# haltium_sysctrl register map
Vendor: Nordic Semiconductor; Series: nRFHaltium; File version: 1
Registers are 32-bit, read-write, reset 0x0 unless marked. A register's access mark holds for its fields unless they carry their own. Offsets are from the block's base; [hi:lo] are bit positions; lines under a group give offsets from that group; {n}, {i} and the like mark numbered series.

## CLIC_S — Core-Local Interrupt Controller
Base 0x5F8C8000
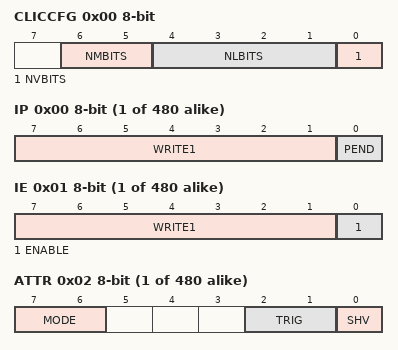
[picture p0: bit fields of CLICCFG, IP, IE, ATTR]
0x00 CLICCFG 8-bit ro — CLIC configuration.
  [6:5] NMBITS — Interrupt previlage mode.
    0=ModeM (All interrupts are M-mode only); 1=ModeS (Interrupts can be S-mode); 2=ModeSU (Interrupts can be S-mode or U-mode)
  [4:1] NLBITS — Interrupt level encoding.
  [0] NVBITS — Selective interrupt hardware vectoring.
    0=NotImplemented (Selective interrupt hardware vectoring is not implemented); 1=Implemented (Selective interrupt hardware vectoring is implemented)
{0x4+i} CLICINFO[{i}] (i=0..3) 8-bit ro — Description collection: CLIC information.
  [7:0] CLICINFO — CLIC information.
{0x1000+4i} CLICINT[{i}] (i=0..479) group — Unspecified
  0x00 IP 8-bit — Description cluster: Interrupt pending for IRQ number [n].
    [7:1] WRITE1 — Read as zero, write 1.
    [0] PEND — Interrupt Pending bit.
      0=NotPending (Interrupt not pending); 1=Pending (Interrupt pending)
  0x01 IE 8-bit — Description cluster: Interrupt enable for IRQ number [n].
    [7:1] WRITE1 — Read as zero, write 1.
    [0] ENABLE — Interrupt enable bit.
      0=Disabled (Interrupt disabled); 1=Enabled (Interrupt enabled)
  0x02 ATTR 8-bit — Description cluster: CLIC Interrupt Attribute Register
    [7:6] MODE — Privilege mode.
      0=UserMode; 1=SupervisorMode; 3=MachineMode
    [2:1] TRIG — Trigger type and polarity for each interrupt input.
      0=EdgeTriggered (Interrupts are edge-triggered); 1=LevelTriggered (Interrupts are level-triggered); 2=NegativeEdge (Interrupts are negative edge-triggered); 3=PositiveEdge (Interrupts are positive edge-triggered)
    [0] SHV — Selective Hardware Vectoring.
      0=NonVectored (Interrupt to be non-vectored); 1=Vectored (Hardware vectored)
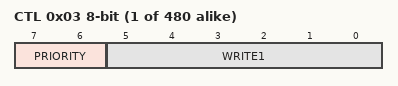
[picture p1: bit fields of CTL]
  0x03 CTL 8-bit — Description cluster: Interrupt priority for IRQ number [n].
    [7:6] PRIORITY — Interrupt priority.
    [5:0] WRITE1 — Read as zero, write 1.

## GLRC0_S — LRC 0
Base 0x5F8CE000
Same registers: GLRC1_S 0x5F93E000
{0x0+4i} TASKS_CLKSTART[{i}] (i=0..7) wo — Description collection: Start the clock source [n]
  [0] TASKS_CLKSTART — Start the clock source [n]
    1=Trigger task
{0x20+4i} TASKS_CLKSTOP[{i}] (i=0..7) wo — Description collection: Clear the TASKS_CLKSTART[n] request
  [0] TASKS_CLKSTOP — Clear the TASKS_CLKSTART[n] request
    1=Trigger task
0x40 TASKS_CONSTLAT wo — Enable constant latency mode
  [0] TASKS_CONSTLAT
    1=Trigger task
0x44 TASKS_LOWPWR wo — Enable Low Power mode
  [0] TASKS_LOWPWR
    1=Trigger task
{0x100+4i} EVENTS_CLKSTARTED[{i}] (i=0..7) — Description collection: Clock [n] started
  [0] EVENTS_CLKSTARTED — Clock [n] started
    0=NotGenerated (Event not generated); 1=Generated (Event generated)
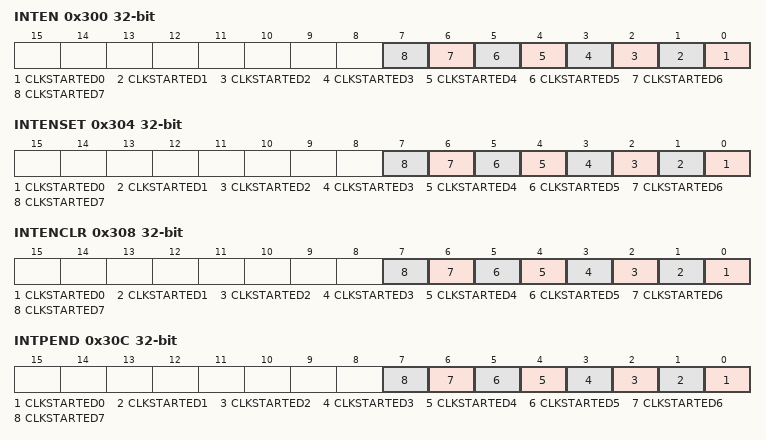
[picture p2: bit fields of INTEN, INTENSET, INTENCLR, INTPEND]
0x300 INTEN — Enable or disable interrupt
  [all] fields
    0=Disabled; 1=Enabled
  [n] CLKSTARTED{n} (n=0..7) — Enable or disable interrupt for event CLKSTARTED[{n}]
0x304 INTENSET — Enable interrupt
  [all] fields
    on read: 0=Disabled (Read: Disabled); 1=Enabled (Read: Enabled) | on write: 1=Set (Enable)
  [n] CLKSTARTED{n} (n=0..7) — Write '1' to enable interrupt for event CLKSTARTED[{n}]
0x308 INTENCLR — Disable interrupt
  [all] fields
    on read: 0=Disabled (Read: Disabled); 1=Enabled (Read: Enabled) | on write: 1=Clear (Disable)
  [n] CLKSTARTED{n} (n=0..7) — Write '1' to disable interrupt for event CLKSTARTED[{n}]
0x30C INTPEND ro — Pending interrupts
  [all] fields
    on read: 0=NotPending (Read: Not pending); 1=Pending (Read: Pending)
  [n] CLKSTARTED{n} (n=0..7) — Read pending status of interrupt for event CLKSTARTED[{n}]
{0x400+8i} CLKSTAT[{i}] (i=0..7) group — Unspecified
  0x00 RUN — Description cluster: Status indicating that TASKS_START task has been triggered for clock [n]
    [0] STATUS — Clock start task triggered or not
      0=NotTriggered (Task not triggered); 1=Triggered (Task triggered)
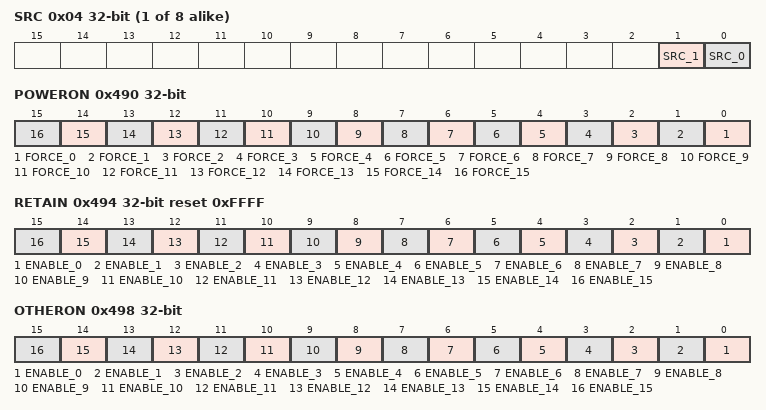
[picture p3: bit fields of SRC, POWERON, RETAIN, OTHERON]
  0x04 SRC — Description cluster: Status indicating which clock source is running for clock [n]
    [1] SRC_1 — Clock source
    [0] SRC_0 — Clock source
{0x440+8i} CLKCTRL[{i}] (i=0..7) group — Unspecified
  0x00 ALWAYSRUN — Description cluster: Force the clock source [n] and tree running always
    [0] FORCE — Force the clock always running
      0=Automatic clock control enabled; 1=AlwaysRun (Clock always running)
  0x04 SRC — Description cluster: Select the clock source for clock [n]
    [1] SRC_1 — Clock source
    [0] SRC_0 — Clock source
0x480 CONSTLATSTAT — Status of constant latency
  [0] STATUS
    0=Low power enabled; 1=ConstLat (Constant latency enabled)
0x490 POWERON — Force power domain ON
  [all] fields
    0=Automatic power control enabled; 1=AlwaysOn (Keep the power domain ON to the domain even though there is no request)
  [n] FORCE_{n} (n=0..15) — Force the power domain ON for domain[{n}]
0x494 RETAIN reset 0xFFFF — Retain power domain
  [all] fields
    0=Disable (Retain disabled); 1=Enable (retain enabled)
  [n] ENABLE_{n} (n=0..15) — Retain the power domain on for domain[{n}]
0x498 OTHERON — Request other domain ON
  [all] fields
    0=Automatic power control enabled; 1=AlwaysOn (Request to keep the other power domain ON to the domain even though there is no request)
  [n] ENABLE_{n} (n=0..15) — Request power domain ON for other domain[{n}]
